AUTOSAR XML (schema 4.0)
standard types defined: float32, float64, sint16, sint32, sint8, uint16, uint32, uint8, void, boolean
package /ImplDataTypes
  impl type MultiStateBtnType: implementation-data-type=sint8, type-emitter=RTE
  impl type StepMotorStepType: implementation-data-type=uint16, type-emitter=RTE
package /MappingSets
  data type mapping set MappingSet
package /PortInterfaces/ClientServer
  client server interface CsIf_HeightStepMotor
    operation HeightMove
      arg step: type=StepMotorStepType, direction=INOUT
  client server interface CsIf_InclineStepMotor
    operation InclineMove
      arg step: type=StepMotorStepType, direction=INOUT
  client server interface CsIf_SlideStepMotor
    operation SlideMove
      arg step: type=StepMotorStepType, direction=INOUT
package /PortInterfaces/SenderReceiver
  sender receiver interface ppSeatCtrlBtns
    data HeightBtnState: type=MultiStateBtnType
    data InclineBtnState: type=MultiStateBtnType
    data SlideBtnState: type=MultiStateBtnType
  sender receiver interface rpSeatCtrlBtns
    data HeightBtnState: type=MultiStateBtnType
    data InclineBtnState: type=MultiStateBtnType
    data SlideBtnState: type=MultiStateBtnType
  sender receiver interface rpSeatCtrlData
    data Height: type=uint8
    data Incline: type=uint8
    data Slide: type=uint8
package /SoftwareComponents
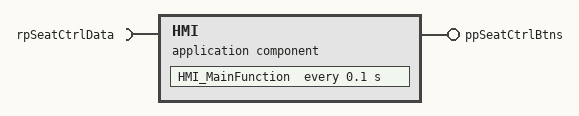
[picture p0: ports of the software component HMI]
  application sw component type HMI
    provide port ppSeatCtrlBtns: provided-interface=ppSeatCtrlBtns
    require port rpSeatCtrlData: required-interface=rpSeatCtrlData
    behavior Ibhv_HMI: data-type-mapping=MappingSet, handle-termination-and-restart=NO-SUPPORT
      timing event TE_HMI_MainFunction_100ms: start-on-event=HMI_MainFunction, period=0.1
      runnable HMI_MainFunction
        data-receive-point-by-arguments:
          access DRP_rpSeatCtrlData_Height: accessed-variable=rpSeatCtrlData.Height
          access DRP_rpSeatCtrlData_Incline: accessed-variable=rpSeatCtrlData.Incline
          access DRP_rpSeatCtrlData_Slide: accessed-variable=rpSeatCtrlData.Slide
        data-send-points:
          access DSP_ppSeatCtrlBtns_HeightBtnState: accessed-variable=ppSeatCtrlBtns.HeightBtnState
          access DSP_ppSeatCtrlBtns_InclineBtnState: accessed-variable=ppSeatCtrlBtns.InclineBtnState
          access DSP_ppSeatCtrlBtns_SlideBtnState: accessed-variable=ppSeatCtrlBtns.SlideBtnState
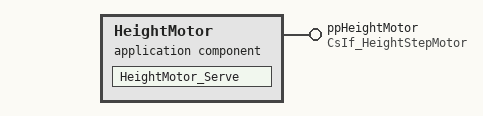
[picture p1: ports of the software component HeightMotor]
  application sw component type HeightMotor
    provide port ppHeightMotor: provided-interface=CsIf_HeightStepMotor
    behavior Ibhv_HeightMotor: data-type-mapping=MappingSet, handle-termination-and-restart=NO-SUPPORT
      operation invoked event OIE_ppHeightMotor_HeightMove: start-on-event=HeightMotor_Serve, operation=ppHeightMotor.HeightMove
      runnable HeightMotor_Serve
  5 x swc implementation, all with programming-language=C, sw-version=1.0.0, vendor-id=255:
    Impl_HMI: behavior=Ibhv_HMI
      code-descriptors:
        code Code: artifact-descriptors=autosar-engineering-object={short-label=SWC.c, category=SWSRC}
      resource consumption ResourceConsumption
    Impl_HeightMotor: behavior=Ibhv_HeightMotor
      code-descriptors:
        code Code: artifact-descriptors=autosar-engineering-object={short-label=SWC.c, category=SWSRC}
      resource consumption ResourceConsumption
    Impl_InclineMotor: behavior=Ibhv_InclineMotor
      code-descriptors:
        code Code: artifact-descriptors=autosar-engineering-object={short-label=SWC.c, category=SWSRC}
      resource consumption ResourceConsumption
    Impl_SeatManager: behavior=Ibhv_SeatManager
      code-descriptors:
        code Code: artifact-descriptors=autosar-engineering-object={short-label=SWC.c, category=SWSRC}
      resource consumption ResourceConsumption
    Impl_SlideMotor: behavior=Ibhv_SlideMotor
      code-descriptors:
        code Code: artifact-descriptors=autosar-engineering-object={short-label=SWC.c, category=SWSRC}
      resource consumption ResourceConsumption
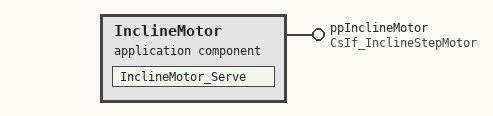
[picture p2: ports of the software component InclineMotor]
  application sw component type InclineMotor
    provide port ppInclineMotor: provided-interface=CsIf_InclineStepMotor
    behavior Ibhv_InclineMotor: data-type-mapping=MappingSet, handle-termination-and-restart=NO-SUPPORT
      operation invoked event OIE_ppInclineMotor_InclineMove: start-on-event=InclineMotor_Serve, operation=ppInclineMotor.InclineMove
      runnable InclineMotor_Serve
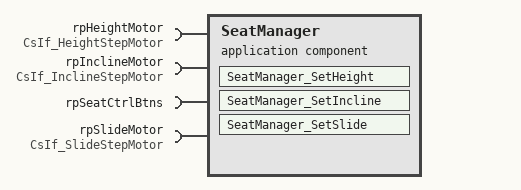
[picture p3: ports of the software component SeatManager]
  application sw component type SeatManager
    4 x require port:
      rpHeightMotor: required-interface=CsIf_HeightStepMotor
      rpInclineMotor: required-interface=CsIf_InclineStepMotor
      rpSeatCtrlBtns: required-interface=rpSeatCtrlBtns
      rpSlideMotor: required-interface=CsIf_SlideStepMotor
    behavior Ibhv_SeatManager: data-type-mapping=MappingSet, handle-termination-and-restart=NO-SUPPORT
      data received event DRE_rpSeatCtrlBtns_HeightBtnState: start-on-event=SeatManager_SetHeight, data=rpSeatCtrlBtns.HeightBtnState
      data received event DRE_rpSeatCtrlBtns_InclineBtnState: start-on-event=SeatManager_SetIncline, data=rpSeatCtrlBtns.InclineBtnState
      data received event DRE_rpSeatCtrlBtns_SlideBtnState: start-on-event=SeatManager_SetSlide, data=rpSeatCtrlBtns.SlideBtnState
      runnable SeatManager_SetHeight
        sync call SCP_rpHeightMotor_HeightMove: operation=rpHeightMotor.HeightMove, timeout=0.0
      runnable SeatManager_SetIncline
        sync call SCP_rpInclineMotor_InclineMove: operation=rpInclineMotor.InclineMove, timeout=0.0
      runnable SeatManager_SetSlide
        sync call SCP_rpSlideMotor_SlideMove: operation=rpSlideMotor.SlideMove, timeout=0.0
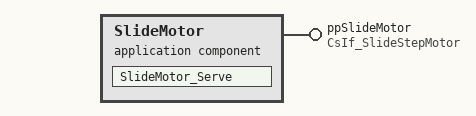
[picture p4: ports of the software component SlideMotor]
  application sw component type SlideMotor
    provide port ppSlideMotor: provided-interface=CsIf_SlideStepMotor
    behavior Ibhv_SlideMotor: data-type-mapping=MappingSet, handle-termination-and-restart=NO-SUPPORT
      operation invoked event OIE_ppSlideMotor_SlideMove: start-on-event=SlideMotor_Serve, operation=ppSlideMotor.SlideMove
      runnable SlideMotor_Serve
package /Compositions
  composition sw component type sender_resceiver_comComposition
